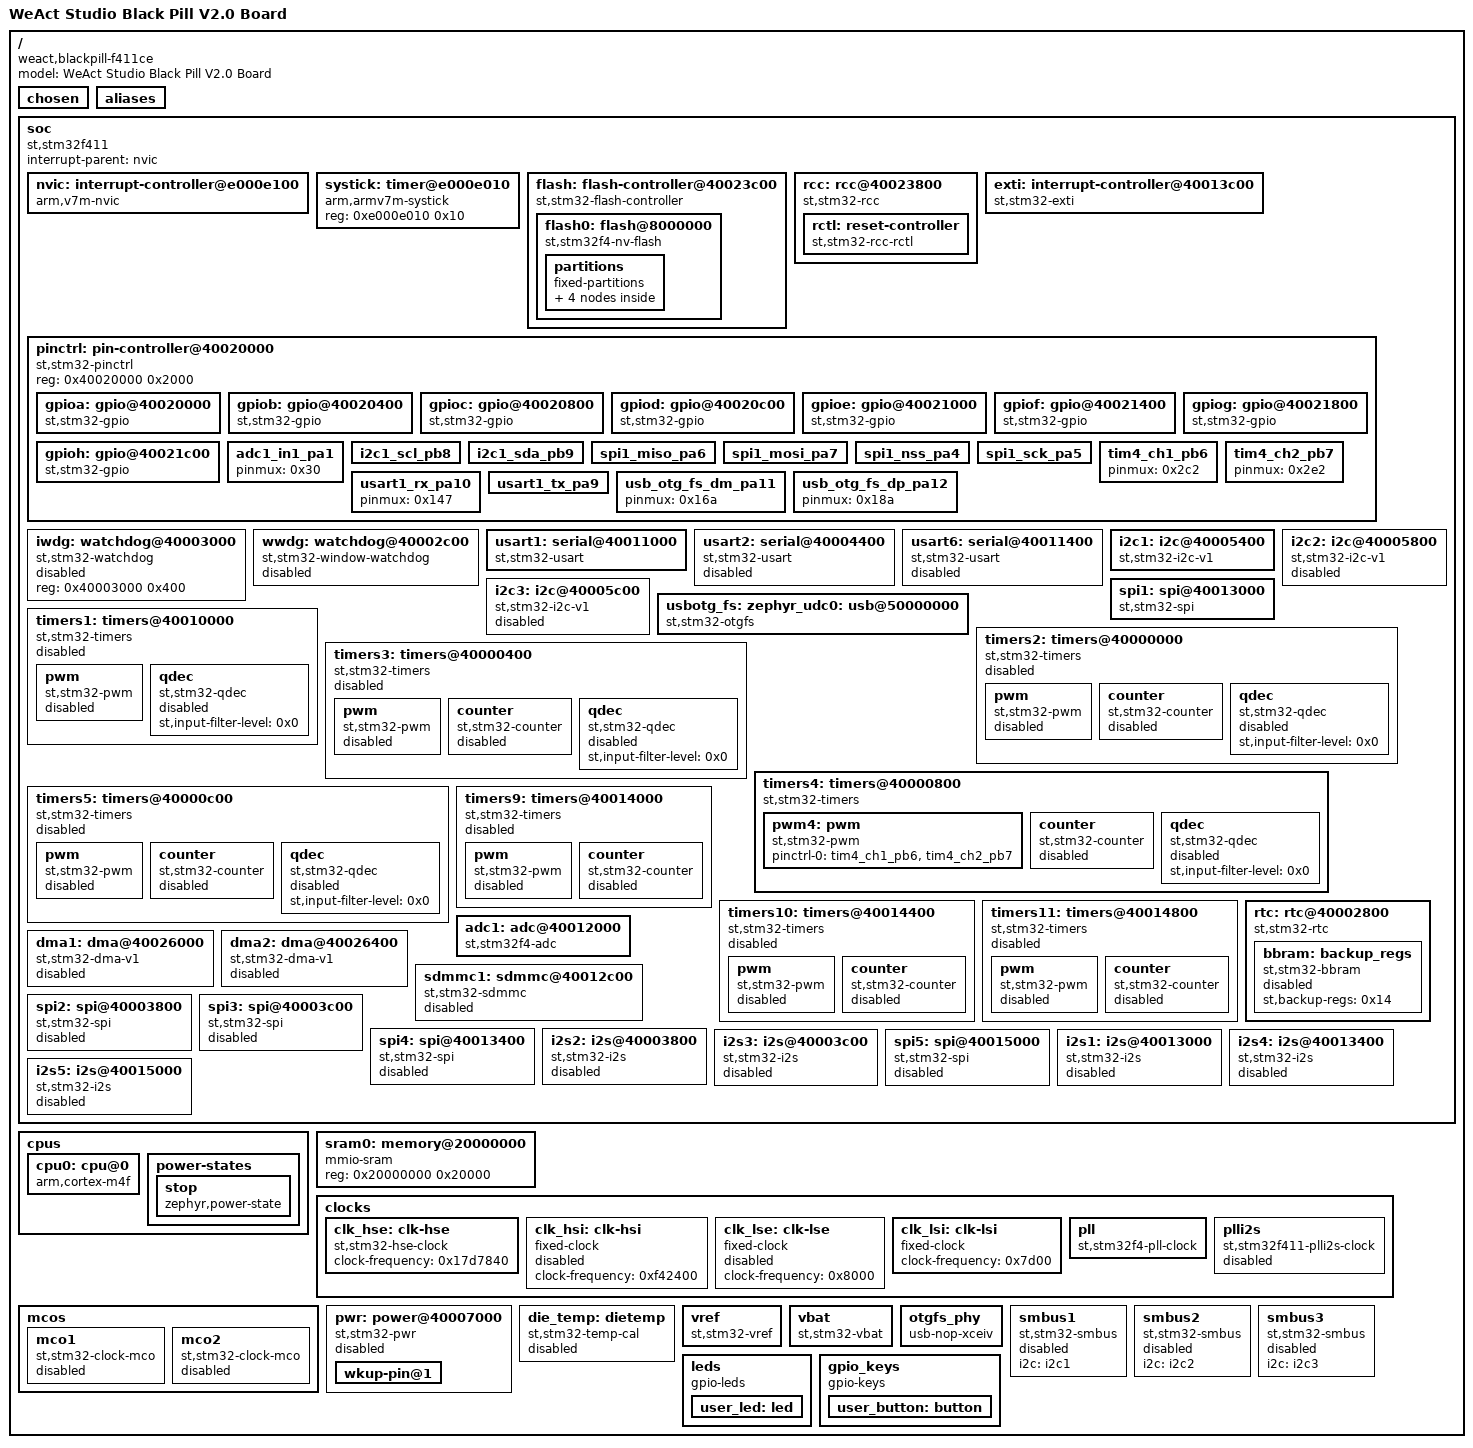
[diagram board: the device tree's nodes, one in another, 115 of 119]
/dts-v1/;

/* node '/' defined in zephyr/dts/common/skeleton.dtsi:9 */
/ {
	#address-cells = < 0x1 >;                     /* in zephyr/dts/common/skeleton.dtsi:10 */
	#size-cells = < 0x1 >;                        /* in zephyr/dts/common/skeleton.dtsi:11 */
	model = "WeAct Studio Black Pill V2.0 Board"; /* in zephyr/boards/weact/blackpill_f411ce/blackpill_f411ce.dts:14 */
	compatible = "weact,blackpill-f411ce";        /* in zephyr/boards/weact/blackpill_f411ce/blackpill_f411ce.dts:15 */

	/* node '/chosen' defined in zephyr/dts/common/skeleton.dtsi:12 */
	chosen {
		zephyr,flash-controller = &flash;        /* in zephyr/dts/arm/st/f4/stm32f4.dtsi:26 */
		zephyr,cortex-m-idle-timer = &rtc;       /* in zephyr/dts/arm/st/f4/stm32f4.dtsi:27 */
		zephyr,console = &usart1;                /* in zephyr/boards/weact/blackpill_f411ce/blackpill_f411ce.dts:18 */
		zephyr,shell-uart = &usart1;             /* in zephyr/boards/weact/blackpill_f411ce/blackpill_f411ce.dts:19 */
		zephyr,sram = &sram0;                    /* in zephyr/boards/weact/blackpill_f411ce/blackpill_f411ce.dts:20 */
		zephyr,flash = &flash0;                  /* in zephyr/boards/weact/blackpill_f411ce/blackpill_f411ce.dts:21 */
		zephyr,code-partition = &boot_partition; /* in bootloader/mcuboot/boot/zephyr/app.overlay:3 */
	};

	/* node '/aliases' defined in zephyr/dts/common/skeleton.dtsi:13 */
	aliases {
		led0 = &user_led;     /* in zephyr/boards/weact/blackpill_f411ce/blackpill_f411ce.dts:42 */
		sw0 = &user_button;   /* in zephyr/boards/weact/blackpill_f411ce/blackpill_f411ce.dts:43 */
		volt-sensor0 = &vref; /* in zephyr/boards/weact/blackpill_f411ce/blackpill_f411ce.dts:44 */
		volt-sensor1 = &vbat; /* in zephyr/boards/weact/blackpill_f411ce/blackpill_f411ce.dts:45 */
	};

	/* node '/soc' defined in zephyr/dts/arm/armv7-m.dtsi:6 */
	soc {
		#address-cells = < 0x1 >;     /* in zephyr/dts/arm/armv7-m.dtsi:7 */
		#size-cells = < 0x1 >;        /* in zephyr/dts/arm/armv7-m.dtsi:8 */
		interrupt-parent = < &nvic >; /* in zephyr/dts/arm/armv7-m.dtsi:10 */
		ranges;                       /* in zephyr/dts/arm/armv7-m.dtsi:11 */
		compatible = "st,stm32f411",
		             "st,stm32f4",
		             "simple-bus";    /* in zephyr/dts/arm/st/f4/stm32f411.dtsi:19 */

		/* node '/soc/interrupt-controller@e000e100' defined in zephyr/dts/arm/armv7-m.dtsi:13 */
		nvic: interrupt-controller@e000e100 {
			#address-cells = < 0x1 >;            /* in zephyr/dts/arm/armv7-m.dtsi:14 */
			compatible = "arm,v7m-nvic";         /* in zephyr/dts/arm/armv7-m.dtsi:15 */
			reg = < 0xe000e100 0xc00 >;          /* in zephyr/dts/arm/armv7-m.dtsi:16 */
			interrupt-controller;                /* in zephyr/dts/arm/armv7-m.dtsi:17 */
			#interrupt-cells = < 0x2 >;          /* in zephyr/dts/arm/armv7-m.dtsi:18 */
			arm,num-irq-priority-bits = < 0x4 >; /* in zephyr/dts/arm/st/f4/stm32f4.dtsi:663 */
			phandle = < 0x1 >;                   /* in zephyr/dts/arm/armv7-m.dtsi:10 */
		};

		/* node '/soc/timer@e000e010' defined in zephyr/dts/arm/armv7-m.dtsi:21 */
		systick: timer@e000e010 {
			compatible = "arm,armv7m-systick"; /* in zephyr/dts/arm/armv7-m.dtsi:22 */
			reg = < 0xe000e010 0x10 >;         /* in zephyr/dts/arm/armv7-m.dtsi:23 */
		};

		/* node '/soc/flash-controller@40023c00' defined in zephyr/dts/arm/st/f4/stm32f4.dtsi:109 */
		flash: flash-controller@40023c00 {
			compatible = "st,stm32-flash-controller",
			             "st,stm32f4-flash-controller"; /* in zephyr/dts/arm/st/f4/stm32f4.dtsi:110 */
			reg = < 0x40023c00 0x400 >;                 /* in zephyr/dts/arm/st/f4/stm32f4.dtsi:111 */
			interrupts = < 0x4 0x0 >;                   /* in zephyr/dts/arm/st/f4/stm32f4.dtsi:112 */
			#address-cells = < 0x1 >;                   /* in zephyr/dts/arm/st/f4/stm32f4.dtsi:114 */
			#size-cells = < 0x1 >;                      /* in zephyr/dts/arm/st/f4/stm32f4.dtsi:115 */

			/* node '/soc/flash-controller@40023c00/flash@8000000' defined in zephyr/dts/arm/st/f4/stm32f4.dtsi:117 */
			flash0: flash@8000000 {
				compatible = "st,stm32f4-nv-flash",
				             "st,stm32-nv-flash",
				             "soc-nv-flash";        /* in zephyr/dts/arm/st/f4/stm32f4.dtsi:118 */
				write-block-size = < 0x1 >;         /* in zephyr/dts/arm/st/f4/stm32f4.dtsi:121 */
				max-erase-time = < 0xfa0 >;         /* in zephyr/dts/arm/st/f4/stm32f4.dtsi:123 */
				reg = < 0x8000000 0x80000 >;        /* in zephyr/dts/arm/st/f4/stm32f411Xe.dtsi:18 */

				/* node '/soc/flash-controller@40023c00/flash@8000000/partitions' defined in zephyr/boards/weact/blackpill_f411ce/blackpill_f411ce.dts:51 */
				partitions {
					compatible = "fixed-partitions"; /* in zephyr/boards/weact/blackpill_f411ce/blackpill_f411ce.dts:52 */
					#address-cells = < 0x1 >;        /* in zephyr/boards/weact/blackpill_f411ce/blackpill_f411ce.dts:53 */
					#size-cells = < 0x1 >;           /* in zephyr/boards/weact/blackpill_f411ce/blackpill_f411ce.dts:54 */

					/* node '/soc/flash-controller@40023c00/flash@8000000/partitions/partition@0' defined in zephyr/boards/weact/blackpill_f411ce/blackpill_f411ce.dts:56 */
					boot_partition: partition@0 {
						label = "mcuboot";    /* in zephyr/boards/weact/blackpill_f411ce/blackpill_f411ce.dts:57 */
						reg = < 0x0 0x8000 >; /* in zephyr/boards/weact/blackpill_f411ce/blackpill_f411ce.dts:58 */
						read-only;            /* in zephyr/boards/weact/blackpill_f411ce/blackpill_f411ce.dts:59 */
					};

					/* node '/soc/flash-controller@40023c00/flash@8000000/partitions/partition@20000' defined in zephyr/boards/weact/blackpill_f411ce/blackpill_f411ce.dts:68 */
					slot0_partition: partition@20000 {
						label = "image-0";         /* in zephyr/boards/weact/blackpill_f411ce/blackpill_f411ce.dts:69 */
						reg = < 0x20000 0x20000 >; /* in zephyr/boards/weact/blackpill_f411ce/blackpill_f411ce.dts:70 */
					};

					/* node '/soc/flash-controller@40023c00/flash@8000000/partitions/partition@40000' defined in zephyr/boards/weact/blackpill_f411ce/blackpill_f411ce.dts:72 */
					slot1_partition: partition@40000 {
						label = "image-1";         /* in zephyr/boards/weact/blackpill_f411ce/blackpill_f411ce.dts:73 */
						reg = < 0x40000 0x20000 >; /* in zephyr/boards/weact/blackpill_f411ce/blackpill_f411ce.dts:74 */
					};

					/* node '/soc/flash-controller@40023c00/flash@8000000/partitions/partition@60000' defined in zephyr/boards/weact/blackpill_f411ce/blackpill_f411ce.dts:76 */
					scratch_partition: partition@60000 {
						label = "image-scratch";   /* in zephyr/boards/weact/blackpill_f411ce/blackpill_f411ce.dts:77 */
						reg = < 0x60000 0x20000 >; /* in zephyr/boards/weact/blackpill_f411ce/blackpill_f411ce.dts:78 */
					};
				};
			};
		};

		/* node '/soc/rcc@40023800' defined in zephyr/dts/arm/st/f4/stm32f4.dtsi:127 */
		rcc: rcc@40023800 {
			compatible = "st,stm32-rcc";     /* in zephyr/dts/arm/st/f4/stm32f4.dtsi:128 */
			#clock-cells = < 0x2 >;          /* in zephyr/dts/arm/st/f4/stm32f4.dtsi:129 */
			reg = < 0x40023800 0x400 >;      /* in zephyr/dts/arm/st/f4/stm32f4.dtsi:130 */
			clocks = < &pll >;               /* in zephyr/boards/weact/blackpill_f411ce/blackpill_f411ce.dts:153 */
			clock-frequency = < 0x5b8d800 >; /* in zephyr/boards/weact/blackpill_f411ce/blackpill_f411ce.dts:154 */
			ahb-prescaler = < 0x1 >;         /* in zephyr/boards/weact/blackpill_f411ce/blackpill_f411ce.dts:155 */
			apb1-prescaler = < 0x2 >;        /* in zephyr/boards/weact/blackpill_f411ce/blackpill_f411ce.dts:156 */
			apb2-prescaler = < 0x1 >;        /* in zephyr/boards/weact/blackpill_f411ce/blackpill_f411ce.dts:157 */
			phandle = < 0x3 >;               /* in zephyr/dts/arm/st/f4/stm32f4.dtsi:164 */

			/* node '/soc/rcc@40023800/reset-controller' defined in zephyr/dts/arm/st/f4/stm32f4.dtsi:132 */
			rctl: reset-controller {
				compatible = "st,stm32-rcc-rctl"; /* in zephyr/dts/arm/st/f4/stm32f4.dtsi:133 */
				#reset-cells = < 0x1 >;           /* in zephyr/dts/arm/st/f4/stm32f4.dtsi:134 */
				phandle = < 0x4 >;                /* in zephyr/dts/arm/st/f4/stm32f4.dtsi:242 */
			};
		};

		/* node '/soc/interrupt-controller@40013c00' defined in zephyr/dts/arm/st/f4/stm32f4.dtsi:138 */
		exti: interrupt-controller@40013c00 {
			compatible = "st,stm32-exti";  /* in zephyr/dts/arm/st/f4/stm32f4.dtsi:139 */
			interrupt-controller;          /* in zephyr/dts/arm/st/f4/stm32f4.dtsi:140 */
			#interrupt-cells = < 0x1 >;    /* in zephyr/dts/arm/st/f4/stm32f4.dtsi:141 */
			#address-cells = < 0x1 >;      /* in zephyr/dts/arm/st/f4/stm32f4.dtsi:142 */
			reg = < 0x40013c00 0x400 >;    /* in zephyr/dts/arm/st/f4/stm32f4.dtsi:143 */
			num-lines = < 0x10 >;          /* in zephyr/dts/arm/st/f4/stm32f4.dtsi:144 */
			interrupts = < 0x6 0x0 >,
			             < 0x7 0x0 >,
			             < 0x8 0x0 >,
			             < 0x9 0x0 >,
			             < 0xa 0x0 >,
			             < 0x17 0x0 >,
			             < 0x28 0x0 >;     /* in zephyr/dts/arm/st/f4/stm32f4.dtsi:145 */
			interrupt-names = "line0",
			                  "line1",
			                  "line2",
			                  "line3",
			                  "line4",
			                  "line5-9",
			                  "line10-15"; /* in zephyr/dts/arm/st/f4/stm32f4.dtsi:147 */
			line-ranges = < 0x0 0x1 >,
			              < 0x1 0x1 >,
			              < 0x2 0x1 >,
			              < 0x3 0x1 >,
			              < 0x4 0x1 >,
			              < 0x5 0x5 >,
			              < 0xa 0x6 >;     /* in zephyr/dts/arm/st/f4/stm32f4.dtsi:149 */
		};

		/* node '/soc/pin-controller@40020000' defined in zephyr/dts/arm/st/f4/stm32f4.dtsi:153 */
		pinctrl: pin-controller@40020000 {
			compatible = "st,stm32-pinctrl"; /* in zephyr/dts/arm/st/f4/stm32f4.dtsi:154 */
			#address-cells = < 0x1 >;        /* in zephyr/dts/arm/st/f4/stm32f4.dtsi:155 */
			#size-cells = < 0x1 >;           /* in zephyr/dts/arm/st/f4/stm32f4.dtsi:156 */
			reg = < 0x40020000 0x2000 >;     /* in zephyr/dts/arm/st/f4/stm32f4.dtsi:157 */

			/* node '/soc/pin-controller@40020000/gpio@40020000' defined in zephyr/dts/arm/st/f4/stm32f4.dtsi:159 */
			gpioa: gpio@40020000 {
				compatible = "st,stm32-gpio"; /* in zephyr/dts/arm/st/f4/stm32f4.dtsi:160 */
				gpio-controller;              /* in zephyr/dts/arm/st/f4/stm32f4.dtsi:161 */
				#gpio-cells = < 0x2 >;        /* in zephyr/dts/arm/st/f4/stm32f4.dtsi:162 */
				reg = < 0x40020000 0x400 >;   /* in zephyr/dts/arm/st/f4/stm32f4.dtsi:163 */
				clocks = < &rcc 0x30 0x1 >;   /* in zephyr/dts/arm/st/f4/stm32f4.dtsi:164 */
				phandle = < 0x17 >;           /* in zephyr/dts/arm/st/f4/stm32f4.dtsi:602 */
			};

			/* node '/soc/pin-controller@40020000/gpio@40020400' defined in zephyr/dts/arm/st/f4/stm32f4.dtsi:167 */
			gpiob: gpio@40020400 {
				compatible = "st,stm32-gpio"; /* in zephyr/dts/arm/st/f4/stm32f4.dtsi:168 */
				gpio-controller;              /* in zephyr/dts/arm/st/f4/stm32f4.dtsi:169 */
				#gpio-cells = < 0x2 >;        /* in zephyr/dts/arm/st/f4/stm32f4.dtsi:170 */
				reg = < 0x40020400 0x400 >;   /* in zephyr/dts/arm/st/f4/stm32f4.dtsi:171 */
				clocks = < &rcc 0x30 0x2 >;   /* in zephyr/dts/arm/st/f4/stm32f4.dtsi:172 */
			};

			/* node '/soc/pin-controller@40020000/gpio@40020800' defined in zephyr/dts/arm/st/f4/stm32f4.dtsi:175 */
			gpioc: gpio@40020800 {
				compatible = "st,stm32-gpio"; /* in zephyr/dts/arm/st/f4/stm32f4.dtsi:176 */
				gpio-controller;              /* in zephyr/dts/arm/st/f4/stm32f4.dtsi:177 */
				#gpio-cells = < 0x2 >;        /* in zephyr/dts/arm/st/f4/stm32f4.dtsi:178 */
				reg = < 0x40020800 0x400 >;   /* in zephyr/dts/arm/st/f4/stm32f4.dtsi:179 */
				clocks = < &rcc 0x30 0x4 >;   /* in zephyr/dts/arm/st/f4/stm32f4.dtsi:180 */
				phandle = < 0x1c >;           /* in zephyr/boards/weact/blackpill_f411ce/blackpill_f411ce.dts:27 */
			};

			/* node '/soc/pin-controller@40020000/gpio@40020c00' defined in zephyr/dts/arm/st/f4/stm32f4.dtsi:183 */
			gpiod: gpio@40020c00 {
				compatible = "st,stm32-gpio"; /* in zephyr/dts/arm/st/f4/stm32f4.dtsi:184 */
				gpio-controller;              /* in zephyr/dts/arm/st/f4/stm32f4.dtsi:185 */
				#gpio-cells = < 0x2 >;        /* in zephyr/dts/arm/st/f4/stm32f4.dtsi:186 */
				reg = < 0x40020c00 0x400 >;   /* in zephyr/dts/arm/st/f4/stm32f4.dtsi:187 */
				clocks = < &rcc 0x30 0x8 >;   /* in zephyr/dts/arm/st/f4/stm32f4.dtsi:188 */
			};

			/* node '/soc/pin-controller@40020000/gpio@40021000' defined in zephyr/dts/arm/st/f4/stm32f4.dtsi:191 */
			gpioe: gpio@40021000 {
				compatible = "st,stm32-gpio"; /* in zephyr/dts/arm/st/f4/stm32f4.dtsi:192 */
				gpio-controller;              /* in zephyr/dts/arm/st/f4/stm32f4.dtsi:193 */
				#gpio-cells = < 0x2 >;        /* in zephyr/dts/arm/st/f4/stm32f4.dtsi:194 */
				reg = < 0x40021000 0x400 >;   /* in zephyr/dts/arm/st/f4/stm32f4.dtsi:195 */
				clocks = < &rcc 0x30 0x10 >;  /* in zephyr/dts/arm/st/f4/stm32f4.dtsi:196 */
			};

			/* node '/soc/pin-controller@40020000/gpio@40021400' defined in zephyr/dts/arm/st/f4/stm32f4.dtsi:199 */
			gpiof: gpio@40021400 {
				compatible = "st,stm32-gpio"; /* in zephyr/dts/arm/st/f4/stm32f4.dtsi:200 */
				gpio-controller;              /* in zephyr/dts/arm/st/f4/stm32f4.dtsi:201 */
				#gpio-cells = < 0x2 >;        /* in zephyr/dts/arm/st/f4/stm32f4.dtsi:202 */
				reg = < 0x40021400 0x400 >;   /* in zephyr/dts/arm/st/f4/stm32f4.dtsi:203 */
				clocks = < &rcc 0x30 0x20 >;  /* in zephyr/dts/arm/st/f4/stm32f4.dtsi:204 */
			};

			/* node '/soc/pin-controller@40020000/gpio@40021800' defined in zephyr/dts/arm/st/f4/stm32f4.dtsi:207 */
			gpiog: gpio@40021800 {
				compatible = "st,stm32-gpio"; /* in zephyr/dts/arm/st/f4/stm32f4.dtsi:208 */
				gpio-controller;              /* in zephyr/dts/arm/st/f4/stm32f4.dtsi:209 */
				#gpio-cells = < 0x2 >;        /* in zephyr/dts/arm/st/f4/stm32f4.dtsi:210 */
				reg = < 0x40021800 0x400 >;   /* in zephyr/dts/arm/st/f4/stm32f4.dtsi:211 */
				clocks = < &rcc 0x30 0x40 >;  /* in zephyr/dts/arm/st/f4/stm32f4.dtsi:212 */
			};

			/* node '/soc/pin-controller@40020000/gpio@40021c00' defined in zephyr/dts/arm/st/f4/stm32f4.dtsi:215 */
			gpioh: gpio@40021c00 {
				compatible = "st,stm32-gpio"; /* in zephyr/dts/arm/st/f4/stm32f4.dtsi:216 */
				gpio-controller;              /* in zephyr/dts/arm/st/f4/stm32f4.dtsi:217 */
				#gpio-cells = < 0x2 >;        /* in zephyr/dts/arm/st/f4/stm32f4.dtsi:218 */
				reg = < 0x40021c00 0x400 >;   /* in zephyr/dts/arm/st/f4/stm32f4.dtsi:219 */
				clocks = < &rcc 0x30 0x80 >;  /* in zephyr/dts/arm/st/f4/stm32f4.dtsi:220 */
			};

			/* node '/soc/pin-controller@40020000/adc1_in1_pa1' defined in modules/hal/stm32/dts/st/f4/stm32f411c(c-e)ux-pinctrl.dtsi:19 */
			adc1_in1_pa1: adc1_in1_pa1 {
				pinmux = < 0x30 >;  /* in modules/hal/stm32/dts/st/f4/stm32f411c(c-e)ux-pinctrl.dtsi:20 */
				phandle = < 0x12 >; /* in zephyr/boards/weact/blackpill_f411ce/blackpill_f411ce.dts:127 */
			};

			/* node '/soc/pin-controller@40020000/i2c1_scl_pb8' defined in modules/hal/stm32/dts/st/f4/stm32f411c(c-e)ux-pinctrl.dtsi:209 */
			i2c1_scl_pb8: i2c1_scl_pb8 {
				pinmux = < 0x304 >; /* in modules/hal/stm32/dts/st/f4/stm32f411c(c-e)ux-pinctrl.dtsi:210 */
				bias-pull-up;       /* in modules/hal/stm32/dts/st/f4/stm32f411c(c-e)ux-pinctrl.dtsi:211 */
				drive-open-drain;   /* in modules/hal/stm32/dts/st/f4/stm32f411c(c-e)ux-pinctrl.dtsi:212 */
				phandle = < 0x7 >;  /* in zephyr/boards/weact/blackpill_f411ce/blackpill_f411ce.dts:101 */
			};

			/* node '/soc/pin-controller@40020000/i2c1_sda_pb9' defined in modules/hal/stm32/dts/st/f4/stm32f411c(c-e)ux-pinctrl.dtsi:235 */
			i2c1_sda_pb9: i2c1_sda_pb9 {
				pinmux = < 0x324 >; /* in modules/hal/stm32/dts/st/f4/stm32f411c(c-e)ux-pinctrl.dtsi:236 */
				bias-pull-up;       /* in modules/hal/stm32/dts/st/f4/stm32f411c(c-e)ux-pinctrl.dtsi:237 */
				drive-open-drain;   /* in modules/hal/stm32/dts/st/f4/stm32f411c(c-e)ux-pinctrl.dtsi:238 */
				phandle = < 0x8 >;  /* in zephyr/boards/weact/blackpill_f411ce/blackpill_f411ce.dts:101 */
			};

			/* node '/soc/pin-controller@40020000/spi1_miso_pa6' defined in modules/hal/stm32/dts/st/f4/stm32f411c(c-e)ux-pinctrl.dtsi:504 */
			spi1_miso_pa6: spi1_miso_pa6 {
				pinmux = < 0xc5 >; /* in modules/hal/stm32/dts/st/f4/stm32f411c(c-e)ux-pinctrl.dtsi:505 */
				bias-pull-down;    /* in modules/hal/stm32/dts/st/f4/stm32f411c(c-e)ux-pinctrl.dtsi:506 */
				phandle = < 0xb >; /* in zephyr/boards/weact/blackpill_f411ce/blackpill_f411ce.dts:108 */
			};

			/* node '/soc/pin-controller@40020000/spi1_mosi_pa7' defined in modules/hal/stm32/dts/st/f4/stm32f411c(c-e)ux-pinctrl.dtsi:536 */
			spi1_mosi_pa7: spi1_mosi_pa7 {
				pinmux = < 0xe5 >; /* in modules/hal/stm32/dts/st/f4/stm32f411c(c-e)ux-pinctrl.dtsi:537 */
				bias-pull-down;    /* in modules/hal/stm32/dts/st/f4/stm32f411c(c-e)ux-pinctrl.dtsi:538 */
				phandle = < 0xc >; /* in zephyr/boards/weact/blackpill_f411ce/blackpill_f411ce.dts:108 */
			};

			/* node '/soc/pin-controller@40020000/spi1_nss_pa4' defined in modules/hal/stm32/dts/st/f4/stm32f411c(c-e)ux-pinctrl.dtsi:573 */
			spi1_nss_pa4: spi1_nss_pa4 {
				pinmux = < 0x85 >; /* in modules/hal/stm32/dts/st/f4/stm32f411c(c-e)ux-pinctrl.dtsi:574 */
				bias-pull-up;      /* in modules/hal/stm32/dts/st/f4/stm32f411c(c-e)ux-pinctrl.dtsi:575 */
				phandle = < 0xa >; /* in zephyr/boards/weact/blackpill_f411ce/blackpill_f411ce.dts:108 */
			};

			/* node '/soc/pin-controller@40020000/spi1_sck_pa5' defined in modules/hal/stm32/dts/st/f4/stm32f411c(c-e)ux-pinctrl.dtsi:615 */
			spi1_sck_pa5: spi1_sck_pa5 {
				pinmux = < 0xa5 >;             /* in modules/hal/stm32/dts/st/f4/stm32f411c(c-e)ux-pinctrl.dtsi:616 */
				bias-pull-down;                /* in modules/hal/stm32/dts/st/f4/stm32f411c(c-e)ux-pinctrl.dtsi:617 */
				slew-rate = "very-high-speed"; /* in modules/hal/stm32/dts/st/f4/stm32f411c(c-e)ux-pinctrl.dtsi:618 */
				phandle = < 0x9 >;             /* in zephyr/boards/weact/blackpill_f411ce/blackpill_f411ce.dts:108 */
			};

			/* node '/soc/pin-controller@40020000/tim4_ch1_pb6' defined in modules/hal/stm32/dts/st/f4/stm32f411c(c-e)ux-pinctrl.dtsi:779 */
			tim4_ch1_pb6: tim4_ch1_pb6 {
				pinmux = < 0x2c2 >; /* in modules/hal/stm32/dts/st/f4/stm32f411c(c-e)ux-pinctrl.dtsi:780 */
				phandle = < 0x10 >; /* in zephyr/boards/weact/blackpill_f411ce/blackpill_f411ce.dts:88 */
			};

			/* node '/soc/pin-controller@40020000/tim4_ch2_pb7' defined in modules/hal/stm32/dts/st/f4/stm32f411c(c-e)ux-pinctrl.dtsi:783 */
			tim4_ch2_pb7: tim4_ch2_pb7 {
				pinmux = < 0x2e2 >; /* in modules/hal/stm32/dts/st/f4/stm32f411c(c-e)ux-pinctrl.dtsi:784 */
				phandle = < 0x11 >; /* in zephyr/boards/weact/blackpill_f411ce/blackpill_f411ce.dts:88 */
			};

			/* node '/soc/pin-controller@40020000/usart1_rx_pa10' defined in modules/hal/stm32/dts/st/f4/stm32f411c(c-e)ux-pinctrl.dtsi:845 */
			usart1_rx_pa10: usart1_rx_pa10 {
				pinmux = < 0x147 >; /* in modules/hal/stm32/dts/st/f4/stm32f411c(c-e)ux-pinctrl.dtsi:846 */
				phandle = < 0x6 >;  /* in zephyr/boards/weact/blackpill_f411ce/blackpill_f411ce.dts:94 */
			};

			/* node '/soc/pin-controller@40020000/usart1_tx_pa9' defined in modules/hal/stm32/dts/st/f4/stm32f411c(c-e)ux-pinctrl.dtsi:867 */
			usart1_tx_pa9: usart1_tx_pa9 {
				pinmux = < 0x127 >; /* in modules/hal/stm32/dts/st/f4/stm32f411c(c-e)ux-pinctrl.dtsi:868 */
				bias-pull-up;       /* in modules/hal/stm32/dts/st/f4/stm32f411c(c-e)ux-pinctrl.dtsi:869 */
				phandle = < 0x5 >;  /* in zephyr/boards/weact/blackpill_f411ce/blackpill_f411ce.dts:94 */
			};

			/* node '/soc/pin-controller@40020000/usb_otg_fs_dm_pa11' defined in modules/hal/stm32/dts/st/f4/stm32f411c(c-e)ux-pinctrl.dtsi:906 */
			usb_otg_fs_dm_pa11: usb_otg_fs_dm_pa11 {
				pinmux = < 0x16a >; /* in modules/hal/stm32/dts/st/f4/stm32f411c(c-e)ux-pinctrl.dtsi:907 */
				phandle = < 0xe >;  /* in zephyr/boards/weact/blackpill_f411ce/blackpill_f411ce.dts:121 */
			};

			/* node '/soc/pin-controller@40020000/usb_otg_fs_dp_pa12' defined in modules/hal/stm32/dts/st/f4/stm32f411c(c-e)ux-pinctrl.dtsi:910 */
			usb_otg_fs_dp_pa12: usb_otg_fs_dp_pa12 {
				pinmux = < 0x18a >; /* in modules/hal/stm32/dts/st/f4/stm32f411c(c-e)ux-pinctrl.dtsi:911 */
				phandle = < 0xf >;  /* in zephyr/boards/weact/blackpill_f411ce/blackpill_f411ce.dts:121 */
			};
		};

		/* node '/soc/watchdog@40003000' defined in zephyr/dts/arm/st/f4/stm32f4.dtsi:224 */
		iwdg: watchdog@40003000 {
			compatible = "st,stm32-watchdog"; /* in zephyr/dts/arm/st/f4/stm32f4.dtsi:225 */
			reg = < 0x40003000 0x400 >;       /* in zephyr/dts/arm/st/f4/stm32f4.dtsi:226 */
			status = "disabled";              /* in zephyr/dts/arm/st/f4/stm32f4.dtsi:227 */
		};

		/* node '/soc/watchdog@40002c00' defined in zephyr/dts/arm/st/f4/stm32f4.dtsi:230 */
		wwdg: watchdog@40002c00 {
			compatible = "st,stm32-window-watchdog"; /* in zephyr/dts/arm/st/f4/stm32f4.dtsi:231 */
			reg = < 0x40002c00 0x400 >;              /* in zephyr/dts/arm/st/f4/stm32f4.dtsi:232 */
			clocks = < &rcc 0x40 0x800 >;            /* in zephyr/dts/arm/st/f4/stm32f4.dtsi:233 */
			interrupts = < 0x0 0x7 >;                /* in zephyr/dts/arm/st/f4/stm32f4.dtsi:234 */
			status = "disabled";                     /* in zephyr/dts/arm/st/f4/stm32f4.dtsi:235 */
		};

		/* node '/soc/serial@40011000' defined in zephyr/dts/arm/st/f4/stm32f4.dtsi:238 */
		usart1: serial@40011000 {
			compatible = "st,stm32-usart",
			             "st,stm32-uart";                   /* in zephyr/dts/arm/st/f4/stm32f4.dtsi:239 */
			reg = < 0x40011000 0x400 >;                     /* in zephyr/dts/arm/st/f4/stm32f4.dtsi:240 */
			clocks = < &rcc 0x44 0x10 >;                    /* in zephyr/dts/arm/st/f4/stm32f4.dtsi:241 */
			resets = < &rctl 0x484 >;                       /* in zephyr/dts/arm/st/f4/stm32f4.dtsi:242 */
			interrupts = < 0x25 0x0 >;                      /* in zephyr/dts/arm/st/f4/stm32f4.dtsi:243 */
			pinctrl-0 = < &usart1_tx_pa9 &usart1_rx_pa10 >; /* in zephyr/boards/weact/blackpill_f411ce/blackpill_f411ce.dts:94 */
			pinctrl-names = "default";                      /* in zephyr/boards/weact/blackpill_f411ce/blackpill_f411ce.dts:95 */
			status = "okay";                                /* in zephyr/boards/weact/blackpill_f411ce/blackpill_f411ce.dts:96 */
			current-speed = < 0x1c200 >;                    /* in zephyr/boards/weact/blackpill_f411ce/blackpill_f411ce.dts:97 */
		};

		/* node '/soc/serial@40004400' defined in zephyr/dts/arm/st/f4/stm32f4.dtsi:247 */
		usart2: serial@40004400 {
			compatible = "st,stm32-usart",
			             "st,stm32-uart";   /* in zephyr/dts/arm/st/f4/stm32f4.dtsi:248 */
			reg = < 0x40004400 0x400 >;     /* in zephyr/dts/arm/st/f4/stm32f4.dtsi:249 */
			clocks = < &rcc 0x40 0x20000 >; /* in zephyr/dts/arm/st/f4/stm32f4.dtsi:250 */
			resets = < &rctl 0x411 >;       /* in zephyr/dts/arm/st/f4/stm32f4.dtsi:251 */
			interrupts = < 0x26 0x0 >;      /* in zephyr/dts/arm/st/f4/stm32f4.dtsi:252 */
			status = "disabled";            /* in zephyr/dts/arm/st/f4/stm32f4.dtsi:253 */
		};

		/* node '/soc/serial@40011400' defined in zephyr/dts/arm/st/f4/stm32f4.dtsi:256 */
		usart6: serial@40011400 {
			compatible = "st,stm32-usart",
			             "st,stm32-uart";  /* in zephyr/dts/arm/st/f4/stm32f4.dtsi:257 */
			reg = < 0x40011400 0x400 >;    /* in zephyr/dts/arm/st/f4/stm32f4.dtsi:258 */
			clocks = < &rcc 0x44 0x20 >;   /* in zephyr/dts/arm/st/f4/stm32f4.dtsi:259 */
			resets = < &rctl 0x485 >;      /* in zephyr/dts/arm/st/f4/stm32f4.dtsi:260 */
			interrupts = < 0x47 0x0 >;     /* in zephyr/dts/arm/st/f4/stm32f4.dtsi:261 */
			status = "disabled";           /* in zephyr/dts/arm/st/f4/stm32f4.dtsi:262 */
		};

		/* node '/soc/i2c@40005400' defined in zephyr/dts/arm/st/f4/stm32f4.dtsi:265 */
		i2c1: i2c@40005400 {
			compatible = "st,stm32-i2c-v1";              /* in zephyr/dts/arm/st/f4/stm32f4.dtsi:266 */
			#address-cells = < 0x1 >;                    /* in zephyr/dts/arm/st/f4/stm32f4.dtsi:268 */
			#size-cells = < 0x0 >;                       /* in zephyr/dts/arm/st/f4/stm32f4.dtsi:269 */
			reg = < 0x40005400 0x400 >;                  /* in zephyr/dts/arm/st/f4/stm32f4.dtsi:270 */
			clocks = < &rcc 0x40 0x200000 >;             /* in zephyr/dts/arm/st/f4/stm32f4.dtsi:271 */
			interrupts = < 0x1f 0x0 >,
			             < 0x20 0x0 >;                   /* in zephyr/dts/arm/st/f4/stm32f4.dtsi:272 */
			interrupt-names = "event",
			                  "error";                   /* in zephyr/dts/arm/st/f4/stm32f4.dtsi:273 */
			pinctrl-0 = < &i2c1_scl_pb8 &i2c1_sda_pb9 >; /* in zephyr/boards/weact/blackpill_f411ce/blackpill_f411ce.dts:101 */
			pinctrl-names = "default";                   /* in zephyr/boards/weact/blackpill_f411ce/blackpill_f411ce.dts:102 */
			status = "okay";                             /* in zephyr/boards/weact/blackpill_f411ce/blackpill_f411ce.dts:103 */
			clock-frequency = < 0x61a80 >;               /* in zephyr/boards/weact/blackpill_f411ce/blackpill_f411ce.dts:104 */
			phandle = < 0x19 >;                          /* in zephyr/dts/arm/st/f4/stm32f4.dtsi:641 */
		};

		/* node '/soc/i2c@40005800' defined in zephyr/dts/arm/st/f4/stm32f4.dtsi:277 */
		i2c2: i2c@40005800 {
			compatible = "st,stm32-i2c-v1";  /* in zephyr/dts/arm/st/f4/stm32f4.dtsi:278 */
			clock-frequency = < 0x186a0 >;   /* in zephyr/dts/arm/st/f4/stm32f4.dtsi:279 */
			#address-cells = < 0x1 >;        /* in zephyr/dts/arm/st/f4/stm32f4.dtsi:280 */
			#size-cells = < 0x0 >;           /* in zephyr/dts/arm/st/f4/stm32f4.dtsi:281 */
			reg = < 0x40005800 0x400 >;      /* in zephyr/dts/arm/st/f4/stm32f4.dtsi:282 */
			clocks = < &rcc 0x40 0x400000 >; /* in zephyr/dts/arm/st/f4/stm32f4.dtsi:283 */
			interrupts = < 0x21 0x0 >,
			             < 0x22 0x0 >;       /* in zephyr/dts/arm/st/f4/stm32f4.dtsi:284 */
			interrupt-names = "event",
			                  "error";       /* in zephyr/dts/arm/st/f4/stm32f4.dtsi:285 */
			status = "disabled";             /* in zephyr/dts/arm/st/f4/stm32f4.dtsi:286 */
			phandle = < 0x1a >;              /* in zephyr/dts/arm/st/f4/stm32f4.dtsi:649 */
		};

		/* node '/soc/i2c@40005c00' defined in zephyr/dts/arm/st/f4/stm32f4.dtsi:289 */
		i2c3: i2c@40005c00 {
			compatible = "st,stm32-i2c-v1";  /* in zephyr/dts/arm/st/f4/stm32f4.dtsi:290 */
			clock-frequency = < 0x186a0 >;   /* in zephyr/dts/arm/st/f4/stm32f4.dtsi:291 */
			#address-cells = < 0x1 >;        /* in zephyr/dts/arm/st/f4/stm32f4.dtsi:292 */
			#size-cells = < 0x0 >;           /* in zephyr/dts/arm/st/f4/stm32f4.dtsi:293 */
			reg = < 0x40005c00 0x400 >;      /* in zephyr/dts/arm/st/f4/stm32f4.dtsi:294 */
			clocks = < &rcc 0x40 0x800000 >; /* in zephyr/dts/arm/st/f4/stm32f4.dtsi:295 */
			interrupts = < 0x48 0x0 >,
			             < 0x49 0x0 >;       /* in zephyr/dts/arm/st/f4/stm32f4.dtsi:296 */
			interrupt-names = "event",
			                  "error";       /* in zephyr/dts/arm/st/f4/stm32f4.dtsi:297 */
			status = "disabled";             /* in zephyr/dts/arm/st/f4/stm32f4.dtsi:298 */
			phandle = < 0x1b >;              /* in zephyr/dts/arm/st/f4/stm32f4.dtsi:657 */
		};

		/* node '/soc/spi@40013000' defined in zephyr/dts/arm/st/f4/stm32f4.dtsi:301 */
		spi1: spi@40013000 {
			compatible = "st,stm32-spi";                                               /* in zephyr/dts/arm/st/f4/stm32f4.dtsi:302 */
			#address-cells = < 0x1 >;                                                  /* in zephyr/dts/arm/st/f4/stm32f4.dtsi:303 */
			#size-cells = < 0x0 >;                                                     /* in zephyr/dts/arm/st/f4/stm32f4.dtsi:304 */
			reg = < 0x40013000 0x400 >;                                                /* in zephyr/dts/arm/st/f4/stm32f4.dtsi:305 */
			clocks = < &rcc 0x44 0x1000 >;                                             /* in zephyr/dts/arm/st/f4/stm32f4.dtsi:306 */
			interrupts = < 0x23 0x5 >;                                                 /* in zephyr/dts/arm/st/f4/stm32f4.dtsi:307 */
			pinctrl-0 = < &spi1_sck_pa5 &spi1_nss_pa4 &spi1_miso_pa6 &spi1_mosi_pa7 >; /* in zephyr/boards/weact/blackpill_f411ce/blackpill_f411ce.dts:108 */
			pinctrl-names = "default";                                                 /* in zephyr/boards/weact/blackpill_f411ce/blackpill_f411ce.dts:110 */
			status = "okay";                                                           /* in zephyr/boards/weact/blackpill_f411ce/blackpill_f411ce.dts:111 */
		};

		/* node '/soc/usb@50000000' defined in zephyr/dts/arm/st/f4/stm32f4.dtsi:311 */
		usbotg_fs: zephyr_udc0: usb@50000000 {
			compatible = "st,stm32-otgfs";                           /* in zephyr/dts/arm/st/f4/stm32f4.dtsi:312 */
			reg = < 0x50000000 0x40000 >;                            /* in zephyr/dts/arm/st/f4/stm32f4.dtsi:313 */
			interrupts = < 0x43 0x0 >;                               /* in zephyr/dts/arm/st/f4/stm32f4.dtsi:314 */
			interrupt-names = "otgfs";                               /* in zephyr/dts/arm/st/f4/stm32f4.dtsi:315 */
			num-bidir-endpoints = < 0x4 >;                           /* in zephyr/dts/arm/st/f4/stm32f4.dtsi:316 */
			ram-size = < 0x500 >;                                    /* in zephyr/dts/arm/st/f4/stm32f4.dtsi:317 */
			maximum-speed = "full-speed";                            /* in zephyr/dts/arm/st/f4/stm32f4.dtsi:318 */
			phys = < &otgfs_phy >;                                   /* in zephyr/dts/arm/st/f4/stm32f4.dtsi:319 */
			clocks = < &rcc 0x34 0x80 >,
			         < &rcc 0x7 0xff >;                              /* in zephyr/dts/arm/st/f4/stm32f4.dtsi:320 */
			pinctrl-0 = < &usb_otg_fs_dm_pa11 &usb_otg_fs_dp_pa12 >; /* in zephyr/boards/weact/blackpill_f411ce/blackpill_f411ce.dts:121 */
			pinctrl-names = "default";                               /* in zephyr/boards/weact/blackpill_f411ce/blackpill_f411ce.dts:122 */
			status = "okay";                                         /* in zephyr/boards/weact/blackpill_f411ce/blackpill_f411ce.dts:123 */
		};

		/* node '/soc/timers@40010000' defined in zephyr/dts/arm/st/f4/stm32f4.dtsi:325 */
		timers1: timers@40010000 {
			compatible = "st,stm32-timers"; /* in zephyr/dts/arm/st/f4/stm32f4.dtsi:326 */
			reg = < 0x40010000 0x400 >;     /* in zephyr/dts/arm/st/f4/stm32f4.dtsi:327 */
			clocks = < &rcc 0x44 0x1 >;     /* in zephyr/dts/arm/st/f4/stm32f4.dtsi:328 */
			resets = < &rctl 0x480 >;       /* in zephyr/dts/arm/st/f4/stm32f4.dtsi:329 */
			interrupts = < 0x18 0x0 >,
			             < 0x19 0x0 >,
			             < 0x1a 0x0 >,
			             < 0x1b 0x0 >;      /* in zephyr/dts/arm/st/f4/stm32f4.dtsi:330 */
			interrupt-names = "brk",
			                  "up",
			                  "trgcom",
			                  "cc";         /* in zephyr/dts/arm/st/f4/stm32f4.dtsi:331 */
			st,prescaler = < 0x0 >;         /* in zephyr/dts/arm/st/f4/stm32f4.dtsi:332 */
			status = "disabled";            /* in zephyr/dts/arm/st/f4/stm32f4.dtsi:333 */

			/* node '/soc/timers@40010000/pwm' defined in zephyr/dts/arm/st/f4/stm32f4.dtsi:335 */
			pwm {
				compatible = "st,stm32-pwm"; /* in zephyr/dts/arm/st/f4/stm32f4.dtsi:336 */
				status = "disabled";         /* in zephyr/dts/arm/st/f4/stm32f4.dtsi:337 */
				#pwm-cells = < 0x3 >;        /* in zephyr/dts/arm/st/f4/stm32f4.dtsi:338 */
			};

			/* node '/soc/timers@40010000/qdec' defined in zephyr/dts/arm/st/f4/stm32f4.dtsi:341 */
			qdec {
				compatible = "st,stm32-qdec";    /* in zephyr/dts/arm/st/f4/stm32f4.dtsi:342 */
				status = "disabled";             /* in zephyr/dts/arm/st/f4/stm32f4.dtsi:343 */
				st,input-filter-level = < 0x0 >; /* in zephyr/dts/arm/st/f4/stm32f4.dtsi:344 */
			};
		};

		/* node '/soc/timers@40000000' defined in zephyr/dts/arm/st/f4/stm32f4.dtsi:348 */
		timers2: timers@40000000 {
			compatible = "st,stm32-timers"; /* in zephyr/dts/arm/st/f4/stm32f4.dtsi:349 */
			reg = < 0x40000000 0x400 >;     /* in zephyr/dts/arm/st/f4/stm32f4.dtsi:350 */
			clocks = < &rcc 0x40 0x1 >;     /* in zephyr/dts/arm/st/f4/stm32f4.dtsi:351 */
			resets = < &rctl 0x400 >;       /* in zephyr/dts/arm/st/f4/stm32f4.dtsi:352 */
			interrupts = < 0x1c 0x0 >;      /* in zephyr/dts/arm/st/f4/stm32f4.dtsi:353 */
			interrupt-names = "global";     /* in zephyr/dts/arm/st/f4/stm32f4.dtsi:354 */
			st,prescaler = < 0x0 >;         /* in zephyr/dts/arm/st/f4/stm32f4.dtsi:355 */
			status = "disabled";            /* in zephyr/dts/arm/st/f4/stm32f4.dtsi:356 */

			/* node '/soc/timers@40000000/pwm' defined in zephyr/dts/arm/st/f4/stm32f4.dtsi:358 */
			pwm {
				compatible = "st,stm32-pwm"; /* in zephyr/dts/arm/st/f4/stm32f4.dtsi:359 */
				status = "disabled";         /* in zephyr/dts/arm/st/f4/stm32f4.dtsi:360 */
				#pwm-cells = < 0x3 >;        /* in zephyr/dts/arm/st/f4/stm32f4.dtsi:361 */
			};

			/* node '/soc/timers@40000000/counter' defined in zephyr/dts/arm/st/f4/stm32f4.dtsi:364 */
			counter {
				compatible = "st,stm32-counter"; /* in zephyr/dts/arm/st/f4/stm32f4.dtsi:365 */
				status = "disabled";             /* in zephyr/dts/arm/st/f4/stm32f4.dtsi:366 */
			};

			/* node '/soc/timers@40000000/qdec' defined in zephyr/dts/arm/st/f4/stm32f4.dtsi:369 */
			qdec {
				compatible = "st,stm32-qdec";    /* in zephyr/dts/arm/st/f4/stm32f4.dtsi:370 */
				status = "disabled";             /* in zephyr/dts/arm/st/f4/stm32f4.dtsi:371 */
				st,input-filter-level = < 0x0 >; /* in zephyr/dts/arm/st/f4/stm32f4.dtsi:372 */
			};
		};

		/* node '/soc/timers@40000400' defined in zephyr/dts/arm/st/f4/stm32f4.dtsi:376 */
		timers3: timers@40000400 {
			compatible = "st,stm32-timers"; /* in zephyr/dts/arm/st/f4/stm32f4.dtsi:377 */
			reg = < 0x40000400 0x400 >;     /* in zephyr/dts/arm/st/f4/stm32f4.dtsi:378 */
			clocks = < &rcc 0x40 0x2 >;     /* in zephyr/dts/arm/st/f4/stm32f4.dtsi:379 */
			resets = < &rctl 0x401 >;       /* in zephyr/dts/arm/st/f4/stm32f4.dtsi:380 */
			interrupts = < 0x1d 0x0 >;      /* in zephyr/dts/arm/st/f4/stm32f4.dtsi:381 */
			interrupt-names = "global";     /* in zephyr/dts/arm/st/f4/stm32f4.dtsi:382 */
			st,prescaler = < 0x0 >;         /* in zephyr/dts/arm/st/f4/stm32f4.dtsi:383 */
			status = "disabled";            /* in zephyr/dts/arm/st/f4/stm32f4.dtsi:384 */

			/* node '/soc/timers@40000400/pwm' defined in zephyr/dts/arm/st/f4/stm32f4.dtsi:386 */
			pwm {
				compatible = "st,stm32-pwm"; /* in zephyr/dts/arm/st/f4/stm32f4.dtsi:387 */
				status = "disabled";         /* in zephyr/dts/arm/st/f4/stm32f4.dtsi:388 */
				#pwm-cells = < 0x3 >;        /* in zephyr/dts/arm/st/f4/stm32f4.dtsi:389 */
			};

			/* node '/soc/timers@40000400/counter' defined in zephyr/dts/arm/st/f4/stm32f4.dtsi:392 */
			counter {
				compatible = "st,stm32-counter"; /* in zephyr/dts/arm/st/f4/stm32f4.dtsi:393 */
				status = "disabled";             /* in zephyr/dts/arm/st/f4/stm32f4.dtsi:394 */
			};

			/* node '/soc/timers@40000400/qdec' defined in zephyr/dts/arm/st/f4/stm32f4.dtsi:397 */
			qdec {
				compatible = "st,stm32-qdec";    /* in zephyr/dts/arm/st/f4/stm32f4.dtsi:398 */
				status = "disabled";             /* in zephyr/dts/arm/st/f4/stm32f4.dtsi:399 */
				st,input-filter-level = < 0x0 >; /* in zephyr/dts/arm/st/f4/stm32f4.dtsi:400 */
			};
		};

		/* node '/soc/timers@40000800' defined in zephyr/dts/arm/st/f4/stm32f4.dtsi:404 */
		timers4: timers@40000800 {
			compatible = "st,stm32-timers"; /* in zephyr/dts/arm/st/f4/stm32f4.dtsi:405 */
			reg = < 0x40000800 0x400 >;     /* in zephyr/dts/arm/st/f4/stm32f4.dtsi:406 */
			clocks = < &rcc 0x40 0x4 >;     /* in zephyr/dts/arm/st/f4/stm32f4.dtsi:407 */
			resets = < &rctl 0x402 >;       /* in zephyr/dts/arm/st/f4/stm32f4.dtsi:408 */
			interrupts = < 0x1e 0x0 >;      /* in zephyr/dts/arm/st/f4/stm32f4.dtsi:409 */
			interrupt-names = "global";     /* in zephyr/dts/arm/st/f4/stm32f4.dtsi:410 */
			st,prescaler = < 0x0 >;         /* in zephyr/dts/arm/st/f4/stm32f4.dtsi:411 */
			status = "okay";                /* in zephyr/boards/weact/blackpill_f411ce/blackpill_f411ce.dts:84 */

			/* node '/soc/timers@40000800/pwm' defined in zephyr/dts/arm/st/f4/stm32f4.dtsi:414 */
			pwm4: pwm {
				compatible = "st,stm32-pwm";                 /* in zephyr/dts/arm/st/f4/stm32f4.dtsi:415 */
				#pwm-cells = < 0x3 >;                        /* in zephyr/dts/arm/st/f4/stm32f4.dtsi:417 */
				status = "okay";                             /* in zephyr/boards/weact/blackpill_f411ce/blackpill_f411ce.dts:87 */
				pinctrl-0 = < &tim4_ch1_pb6 &tim4_ch2_pb7 >; /* in zephyr/boards/weact/blackpill_f411ce/blackpill_f411ce.dts:88 */
				pinctrl-names = "default";                   /* in zephyr/boards/weact/blackpill_f411ce/blackpill_f411ce.dts:89 */
			};

			/* node '/soc/timers@40000800/counter' defined in zephyr/dts/arm/st/f4/stm32f4.dtsi:420 */
			counter {
				compatible = "st,stm32-counter"; /* in zephyr/dts/arm/st/f4/stm32f4.dtsi:421 */
				status = "disabled";             /* in zephyr/dts/arm/st/f4/stm32f4.dtsi:422 */
			};

			/* node '/soc/timers@40000800/qdec' defined in zephyr/dts/arm/st/f4/stm32f4.dtsi:425 */
			qdec {
				compatible = "st,stm32-qdec";    /* in zephyr/dts/arm/st/f4/stm32f4.dtsi:426 */
				status = "disabled";             /* in zephyr/dts/arm/st/f4/stm32f4.dtsi:427 */
				st,input-filter-level = < 0x0 >; /* in zephyr/dts/arm/st/f4/stm32f4.dtsi:428 */
			};
		};

		/* node '/soc/timers@40000c00' defined in zephyr/dts/arm/st/f4/stm32f4.dtsi:432 */
		timers5: timers@40000c00 {
			compatible = "st,stm32-timers"; /* in zephyr/dts/arm/st/f4/stm32f4.dtsi:433 */
			reg = < 0x40000c00 0x400 >;     /* in zephyr/dts/arm/st/f4/stm32f4.dtsi:434 */
			clocks = < &rcc 0x40 0x8 >;     /* in zephyr/dts/arm/st/f4/stm32f4.dtsi:435 */
			resets = < &rctl 0x403 >;       /* in zephyr/dts/arm/st/f4/stm32f4.dtsi:436 */
			interrupts = < 0x32 0x0 >;      /* in zephyr/dts/arm/st/f4/stm32f4.dtsi:437 */
			interrupt-names = "global";     /* in zephyr/dts/arm/st/f4/stm32f4.dtsi:438 */
			st,prescaler = < 0x0 >;         /* in zephyr/dts/arm/st/f4/stm32f4.dtsi:439 */
			status = "disabled";            /* in zephyr/dts/arm/st/f4/stm32f4.dtsi:440 */

			/* node '/soc/timers@40000c00/pwm' defined in zephyr/dts/arm/st/f4/stm32f4.dtsi:442 */
			pwm {
				compatible = "st,stm32-pwm"; /* in zephyr/dts/arm/st/f4/stm32f4.dtsi:443 */
				status = "disabled";         /* in zephyr/dts/arm/st/f4/stm32f4.dtsi:444 */
				#pwm-cells = < 0x3 >;        /* in zephyr/dts/arm/st/f4/stm32f4.dtsi:445 */
			};

			/* node '/soc/timers@40000c00/counter' defined in zephyr/dts/arm/st/f4/stm32f4.dtsi:448 */
			counter {
				compatible = "st,stm32-counter"; /* in zephyr/dts/arm/st/f4/stm32f4.dtsi:449 */
				status = "disabled";             /* in zephyr/dts/arm/st/f4/stm32f4.dtsi:450 */
			};

			/* node '/soc/timers@40000c00/qdec' defined in zephyr/dts/arm/st/f4/stm32f4.dtsi:453 */
			qdec {
				compatible = "st,stm32-qdec";    /* in zephyr/dts/arm/st/f4/stm32f4.dtsi:454 */
				status = "disabled";             /* in zephyr/dts/arm/st/f4/stm32f4.dtsi:455 */
				st,input-filter-level = < 0x0 >; /* in zephyr/dts/arm/st/f4/stm32f4.dtsi:456 */
			};
		};

		/* node '/soc/timers@40014000' defined in zephyr/dts/arm/st/f4/stm32f4.dtsi:460 */
		timers9: timers@40014000 {
			compatible = "st,stm32-timers"; /* in zephyr/dts/arm/st/f4/stm32f4.dtsi:461 */
			reg = < 0x40014000 0x400 >;     /* in zephyr/dts/arm/st/f4/stm32f4.dtsi:462 */
			clocks = < &rcc 0x44 0x10000 >; /* in zephyr/dts/arm/st/f4/stm32f4.dtsi:463 */
			resets = < &rctl 0x490 >;       /* in zephyr/dts/arm/st/f4/stm32f4.dtsi:464 */
			interrupts = < 0x18 0x0 >;      /* in zephyr/dts/arm/st/f4/stm32f4.dtsi:465 */
			interrupt-names = "global";     /* in zephyr/dts/arm/st/f4/stm32f4.dtsi:466 */
			st,prescaler = < 0x0 >;         /* in zephyr/dts/arm/st/f4/stm32f4.dtsi:467 */
			status = "disabled";            /* in zephyr/dts/arm/st/f4/stm32f4.dtsi:468 */

			/* node '/soc/timers@40014000/pwm' defined in zephyr/dts/arm/st/f4/stm32f4.dtsi:470 */
			pwm {
				compatible = "st,stm32-pwm"; /* in zephyr/dts/arm/st/f4/stm32f4.dtsi:471 */
				status = "disabled";         /* in zephyr/dts/arm/st/f4/stm32f4.dtsi:472 */
				#pwm-cells = < 0x3 >;        /* in zephyr/dts/arm/st/f4/stm32f4.dtsi:473 */
			};

			/* node '/soc/timers@40014000/counter' defined in zephyr/dts/arm/st/f4/stm32f4.dtsi:476 */
			counter {
				compatible = "st,stm32-counter"; /* in zephyr/dts/arm/st/f4/stm32f4.dtsi:477 */
				status = "disabled";             /* in zephyr/dts/arm/st/f4/stm32f4.dtsi:478 */
			};
		};

		/* node '/soc/timers@40014400' defined in zephyr/dts/arm/st/f4/stm32f4.dtsi:482 */
		timers10: timers@40014400 {
			compatible = "st,stm32-timers"; /* in zephyr/dts/arm/st/f4/stm32f4.dtsi:483 */
			reg = < 0x40014400 0x400 >;     /* in zephyr/dts/arm/st/f4/stm32f4.dtsi:484 */
			clocks = < &rcc 0x44 0x20000 >; /* in zephyr/dts/arm/st/f4/stm32f4.dtsi:485 */
			resets = < &rctl 0x491 >;       /* in zephyr/dts/arm/st/f4/stm32f4.dtsi:486 */
			interrupts = < 0x19 0x0 >;      /* in zephyr/dts/arm/st/f4/stm32f4.dtsi:487 */
			interrupt-names = "global";     /* in zephyr/dts/arm/st/f4/stm32f4.dtsi:488 */
			st,prescaler = < 0x0 >;         /* in zephyr/dts/arm/st/f4/stm32f4.dtsi:489 */
			status = "disabled";            /* in zephyr/dts/arm/st/f4/stm32f4.dtsi:490 */

			/* node '/soc/timers@40014400/pwm' defined in zephyr/dts/arm/st/f4/stm32f4.dtsi:492 */
			pwm {
				compatible = "st,stm32-pwm"; /* in zephyr/dts/arm/st/f4/stm32f4.dtsi:493 */
				status = "disabled";         /* in zephyr/dts/arm/st/f4/stm32f4.dtsi:494 */
				#pwm-cells = < 0x3 >;        /* in zephyr/dts/arm/st/f4/stm32f4.dtsi:495 */
			};

			/* node '/soc/timers@40014400/counter' defined in zephyr/dts/arm/st/f4/stm32f4.dtsi:498 */
			counter {
				compatible = "st,stm32-counter"; /* in zephyr/dts/arm/st/f4/stm32f4.dtsi:499 */
				status = "disabled";             /* in zephyr/dts/arm/st/f4/stm32f4.dtsi:500 */
			};
		};

		/* node '/soc/timers@40014800' defined in zephyr/dts/arm/st/f4/stm32f4.dtsi:504 */
		timers11: timers@40014800 {
			compatible = "st,stm32-timers"; /* in zephyr/dts/arm/st/f4/stm32f4.dtsi:505 */
			reg = < 0x40014800 0x400 >;     /* in zephyr/dts/arm/st/f4/stm32f4.dtsi:506 */
			clocks = < &rcc 0x44 0x40000 >; /* in zephyr/dts/arm/st/f4/stm32f4.dtsi:507 */
			resets = < &rctl 0x492 >;       /* in zephyr/dts/arm/st/f4/stm32f4.dtsi:508 */
			interrupts = < 0x1a 0x0 >;      /* in zephyr/dts/arm/st/f4/stm32f4.dtsi:509 */
			interrupt-names = "global";     /* in zephyr/dts/arm/st/f4/stm32f4.dtsi:510 */
			st,prescaler = < 0x0 >;         /* in zephyr/dts/arm/st/f4/stm32f4.dtsi:511 */
			status = "disabled";            /* in zephyr/dts/arm/st/f4/stm32f4.dtsi:512 */

			/* node '/soc/timers@40014800/pwm' defined in zephyr/dts/arm/st/f4/stm32f4.dtsi:514 */
			pwm {
				compatible = "st,stm32-pwm"; /* in zephyr/dts/arm/st/f4/stm32f4.dtsi:515 */
				status = "disabled";         /* in zephyr/dts/arm/st/f4/stm32f4.dtsi:516 */
				#pwm-cells = < 0x3 >;        /* in zephyr/dts/arm/st/f4/stm32f4.dtsi:517 */
			};

			/* node '/soc/timers@40014800/counter' defined in zephyr/dts/arm/st/f4/stm32f4.dtsi:520 */
			counter {
				compatible = "st,stm32-counter"; /* in zephyr/dts/arm/st/f4/stm32f4.dtsi:521 */
				status = "disabled";             /* in zephyr/dts/arm/st/f4/stm32f4.dtsi:522 */
			};
		};

		/* node '/soc/rtc@40002800' defined in zephyr/dts/arm/st/f4/stm32f4.dtsi:526 */
		rtc: rtc@40002800 {
			compatible = "st,stm32-rtc";       /* in zephyr/dts/arm/st/f4/stm32f4.dtsi:527 */
			reg = < 0x40002800 0x400 >;        /* in zephyr/dts/arm/st/f4/stm32f4.dtsi:528 */
			interrupts = < 0x29 0x0 >;         /* in zephyr/dts/arm/st/f4/stm32f4.dtsi:529 */
			prescaler = < 0x8000 >;            /* in zephyr/dts/arm/st/f4/stm32f4.dtsi:531 */
			alarms-count = < 0x2 >;            /* in zephyr/dts/arm/st/f4/stm32f4.dtsi:532 */
			alrm-exti-line = < 0x11 >;         /* in zephyr/dts/arm/st/f4/stm32f4.dtsi:533 */
			clocks = < &rcc 0x40 0x10000000 >,
			         < &rcc 0x3 0x10c80070 >;  /* in zephyr/boards/weact/blackpill_f411ce/blackpill_f411ce.dts:115 */
			status = "okay";                   /* in zephyr/boards/weact/blackpill_f411ce/blackpill_f411ce.dts:117 */

			/* node '/soc/rtc@40002800/backup_regs' defined in zephyr/dts/arm/st/f4/stm32f4.dtsi:536 */
			bbram: backup_regs {
				compatible = "st,stm32-bbram"; /* in zephyr/dts/arm/st/f4/stm32f4.dtsi:537 */
				st,backup-regs = < 0x14 >;     /* in zephyr/dts/arm/st/f4/stm32f4.dtsi:538 */
				status = "disabled";           /* in zephyr/dts/arm/st/f4/stm32f4.dtsi:539 */
			};
		};

		/* node '/soc/adc@40012000' defined in zephyr/dts/arm/st/f4/stm32f4.dtsi:543 */
		adc1: adc@40012000 {
			compatible = "st,stm32f4-adc",
			             "st,stm32-adc";                                 /* in zephyr/dts/arm/st/f4/stm32f4.dtsi:544 */
			reg = < 0x40012000 0x400 >;                                  /* in zephyr/dts/arm/st/f4/stm32f4.dtsi:545 */
			clocks = < &rcc 0x44 0x100 >;                                /* in zephyr/dts/arm/st/f4/stm32f4.dtsi:546 */
			interrupts = < 0x12 0x0 >;                                   /* in zephyr/dts/arm/st/f4/stm32f4.dtsi:547 */
			#io-channel-cells = < 0x1 >;                                 /* in zephyr/dts/arm/st/f4/stm32f4.dtsi:549 */
			resolutions = < 0x607804 0x517804 0x427804 0x337804 >;       /* in zephyr/dts/arm/st/f4/stm32f4.dtsi:550 */
			sampling-times = < 0x3 0xf 0x1c 0x38 0x54 0x70 0x90 0x1e0 >; /* in zephyr/dts/arm/st/f4/stm32f4.dtsi:554 */
			st,adc-sequencer = "FULLY_CONFIGURABLE";                     /* in zephyr/dts/arm/st/f4/stm32f4.dtsi:556 */
			st,adc-oversampler = "OVERSAMPLER_NONE";                     /* in zephyr/dts/arm/st/f4/stm32f4.dtsi:557 */
			pinctrl-0 = < &adc1_in1_pa1 >;                               /* in zephyr/boards/weact/blackpill_f411ce/blackpill_f411ce.dts:127 */
			pinctrl-names = "default";                                   /* in zephyr/boards/weact/blackpill_f411ce/blackpill_f411ce.dts:128 */
			st,adc-clock-source = "SYNC";                                /* in zephyr/boards/weact/blackpill_f411ce/blackpill_f411ce.dts:129 */
			st,adc-prescaler = < 0x2 >;                                  /* in zephyr/boards/weact/blackpill_f411ce/blackpill_f411ce.dts:130 */
			status = "okay";                                             /* in zephyr/boards/weact/blackpill_f411ce/blackpill_f411ce.dts:131 */
			phandle = < 0x18 >;                                          /* in zephyr/dts/arm/st/f4/stm32f411.dtsi:72 */
		};

		/* node '/soc/dma@40026000' defined in zephyr/dts/arm/st/f4/stm32f4.dtsi:560 */
		dma1: dma@40026000 {
			compatible = "st,stm32-dma-v1";                                                      /* in zephyr/dts/arm/st/f4/stm32f4.dtsi:561 */
			#dma-cells = < 0x4 >;                                                                /* in zephyr/dts/arm/st/f4/stm32f4.dtsi:562 */
			reg = < 0x40026000 0x400 >;                                                          /* in zephyr/dts/arm/st/f4/stm32f4.dtsi:563 */
			interrupts = < 0xb 0x0 0xc 0x0 0xd 0x0 0xe 0x0 0xf 0x0 0x10 0x0 0x11 0x0 0x2f 0x0 >; /* in zephyr/dts/arm/st/f4/stm32f4.dtsi:564 */
			clocks = < &rcc 0x30 0x200000 >;                                                     /* in zephyr/dts/arm/st/f4/stm32f4.dtsi:565 */
			status = "disabled";                                                                 /* in zephyr/dts/arm/st/f4/stm32f4.dtsi:566 */
			phandle = < 0x13 >;                                                                  /* in zephyr/dts/arm/st/f4/stm32f401.dtsi:58 */
		};

		/* node '/soc/dma@40026400' defined in zephyr/dts/arm/st/f4/stm32f4.dtsi:569 */
		dma2: dma@40026400 {
			compatible = "st,stm32-dma-v1";                                                           /* in zephyr/dts/arm/st/f4/stm32f4.dtsi:570 */
			#dma-cells = < 0x4 >;                                                                     /* in zephyr/dts/arm/st/f4/stm32f4.dtsi:571 */
			reg = < 0x40026400 0x400 >;                                                               /* in zephyr/dts/arm/st/f4/stm32f4.dtsi:572 */
			interrupts = < 0x38 0x0 0x39 0x0 0x3a 0x0 0x3b 0x0 0x3c 0x0 0x44 0x0 0x45 0x0 0x46 0x0 >; /* in zephyr/dts/arm/st/f4/stm32f4.dtsi:573 */
			clocks = < &rcc 0x30 0x400000 >;                                                          /* in zephyr/dts/arm/st/f4/stm32f4.dtsi:574 */
			st,mem2mem;                                                                               /* in zephyr/dts/arm/st/f4/stm32f4.dtsi:575 */
			status = "disabled";                                                                      /* in zephyr/dts/arm/st/f4/stm32f4.dtsi:576 */
			phandle = < 0x14 >;                                                                       /* in zephyr/dts/arm/st/f4/stm32f411.dtsi:38 */
		};

		/* node '/soc/sdmmc@40012c00' defined in zephyr/dts/arm/st/f4/stm32f4.dtsi:579 */
		sdmmc1: sdmmc@40012c00 {
			compatible = "st,stm32-sdmmc"; /* in zephyr/dts/arm/st/f4/stm32f4.dtsi:580 */
			reg = < 0x40012c00 0x400 >;    /* in zephyr/dts/arm/st/f4/stm32f4.dtsi:581 */
			clocks = < &rcc 0x44 0x800 >,
			         < &rcc 0x7 0xff >;    /* in zephyr/dts/arm/st/f4/stm32f4.dtsi:582 */
			resets = < &rctl 0x48b >;      /* in zephyr/dts/arm/st/f4/stm32f4.dtsi:584 */
			interrupts = < 0x31 0x0 >;     /* in zephyr/dts/arm/st/f4/stm32f4.dtsi:585 */
			status = "disabled";           /* in zephyr/dts/arm/st/f4/stm32f4.dtsi:586 */
		};

		/* node '/soc/spi@40003800' defined in zephyr/dts/arm/st/f4/stm32f401.dtsi:21 */
		spi2: spi@40003800 {
			compatible = "st,stm32-spi";   /* in zephyr/dts/arm/st/f4/stm32f401.dtsi:22 */
			#address-cells = < 0x1 >;      /* in zephyr/dts/arm/st/f4/stm32f401.dtsi:23 */
			#size-cells = < 0x0 >;         /* in zephyr/dts/arm/st/f4/stm32f401.dtsi:24 */
			reg = < 0x40003800 0x400 >;    /* in zephyr/dts/arm/st/f4/stm32f401.dtsi:25 */
			clocks = < &rcc 0x40 0x4000 >; /* in zephyr/dts/arm/st/f4/stm32f401.dtsi:26 */
			interrupts = < 0x24 0x5 >;     /* in zephyr/dts/arm/st/f4/stm32f401.dtsi:27 */
			status = "disabled";           /* in zephyr/dts/arm/st/f4/stm32f401.dtsi:28 */
		};

		/* node '/soc/spi@40003c00' defined in zephyr/dts/arm/st/f4/stm32f401.dtsi:31 */
		spi3: spi@40003c00 {
			compatible = "st,stm32-spi";   /* in zephyr/dts/arm/st/f4/stm32f401.dtsi:32 */
			#address-cells = < 0x1 >;      /* in zephyr/dts/arm/st/f4/stm32f401.dtsi:33 */
			#size-cells = < 0x0 >;         /* in zephyr/dts/arm/st/f4/stm32f401.dtsi:34 */
			reg = < 0x40003c00 0x400 >;    /* in zephyr/dts/arm/st/f4/stm32f401.dtsi:35 */
			clocks = < &rcc 0x40 0x8000 >; /* in zephyr/dts/arm/st/f4/stm32f401.dtsi:36 */
			interrupts = < 0x33 0x5 >;     /* in zephyr/dts/arm/st/f4/stm32f401.dtsi:37 */
			status = "disabled";           /* in zephyr/dts/arm/st/f4/stm32f401.dtsi:38 */
		};

		/* node '/soc/spi@40013400' defined in zephyr/dts/arm/st/f4/stm32f401.dtsi:41 */
		spi4: spi@40013400 {
			compatible = "st,stm32-spi";   /* in zephyr/dts/arm/st/f4/stm32f401.dtsi:42 */
			#address-cells = < 0x1 >;      /* in zephyr/dts/arm/st/f4/stm32f401.dtsi:43 */
			#size-cells = < 0x0 >;         /* in zephyr/dts/arm/st/f4/stm32f401.dtsi:44 */
			reg = < 0x40013400 0x400 >;    /* in zephyr/dts/arm/st/f4/stm32f401.dtsi:45 */
			clocks = < &rcc 0x44 0x2000 >; /* in zephyr/dts/arm/st/f4/stm32f401.dtsi:46 */
			interrupts = < 0x54 0x5 >;     /* in zephyr/dts/arm/st/f4/stm32f401.dtsi:47 */
			status = "disabled";           /* in zephyr/dts/arm/st/f4/stm32f401.dtsi:48 */
		};

		/* node '/soc/i2s@40003800' defined in zephyr/dts/arm/st/f4/stm32f401.dtsi:51 */
		i2s2: i2s@40003800 {
			compatible = "st,stm32-i2s";                                /* in zephyr/dts/arm/st/f4/stm32f401.dtsi:52 */
			#address-cells = < 0x1 >;                                   /* in zephyr/dts/arm/st/f4/stm32f401.dtsi:53 */
			#size-cells = < 0x0 >;                                      /* in zephyr/dts/arm/st/f4/stm32f401.dtsi:54 */
			reg = < 0x40003800 0x400 >;                                 /* in zephyr/dts/arm/st/f4/stm32f401.dtsi:55 */
			clocks = < &rcc 0x40 0x4000 >;                              /* in zephyr/dts/arm/st/f4/stm32f401.dtsi:56 */
			interrupts = < 0x24 0x5 >;                                  /* in zephyr/dts/arm/st/f4/stm32f401.dtsi:57 */
			dmas = < &dma1 0x4 0x0 0x400 0x3 &dma1 0x3 0x0 0x400 0x3 >; /* in zephyr/dts/arm/st/f4/stm32f401.dtsi:58 */
			dma-names = "tx",
			            "rx";                                           /* in zephyr/dts/arm/st/f4/stm32f401.dtsi:60 */
			status = "disabled";                                        /* in zephyr/dts/arm/st/f4/stm32f401.dtsi:61 */
		};

		/* node '/soc/i2s@40003c00' defined in zephyr/dts/arm/st/f4/stm32f401.dtsi:64 */
		i2s3: i2s@40003c00 {
			compatible = "st,stm32-i2s";                                /* in zephyr/dts/arm/st/f4/stm32f401.dtsi:65 */
			#address-cells = < 0x1 >;                                   /* in zephyr/dts/arm/st/f4/stm32f401.dtsi:66 */
			#size-cells = < 0x0 >;                                      /* in zephyr/dts/arm/st/f4/stm32f401.dtsi:67 */
			reg = < 0x40003c00 0x400 >;                                 /* in zephyr/dts/arm/st/f4/stm32f401.dtsi:68 */
			clocks = < &rcc 0x40 0x8000 >;                              /* in zephyr/dts/arm/st/f4/stm32f401.dtsi:69 */
			interrupts = < 0x33 0x5 >;                                  /* in zephyr/dts/arm/st/f4/stm32f401.dtsi:70 */
			dmas = < &dma1 0x5 0x0 0x400 0x3 &dma1 0x0 0x0 0x400 0x3 >; /* in zephyr/dts/arm/st/f4/stm32f401.dtsi:71 */
			dma-names = "tx",
			            "rx";                                           /* in zephyr/dts/arm/st/f4/stm32f401.dtsi:73 */
			status = "disabled";                                        /* in zephyr/dts/arm/st/f4/stm32f401.dtsi:74 */
		};

		/* node '/soc/spi@40015000' defined in zephyr/dts/arm/st/f4/stm32f411.dtsi:21 */
		spi5: spi@40015000 {
			compatible = "st,stm32-spi";     /* in zephyr/dts/arm/st/f4/stm32f411.dtsi:22 */
			#address-cells = < 0x1 >;        /* in zephyr/dts/arm/st/f4/stm32f411.dtsi:23 */
			#size-cells = < 0x0 >;           /* in zephyr/dts/arm/st/f4/stm32f411.dtsi:24 */
			reg = < 0x40015000 0x400 >;      /* in zephyr/dts/arm/st/f4/stm32f411.dtsi:25 */
			clocks = < &rcc 0x44 0x100000 >; /* in zephyr/dts/arm/st/f4/stm32f411.dtsi:26 */
			interrupts = < 0x55 0x5 >;       /* in zephyr/dts/arm/st/f4/stm32f411.dtsi:27 */
			status = "disabled";             /* in zephyr/dts/arm/st/f4/stm32f411.dtsi:28 */
		};

		/* node '/soc/i2s@40013000' defined in zephyr/dts/arm/st/f4/stm32f411.dtsi:31 */
		i2s1: i2s@40013000 {
			compatible = "st,stm32-i2s";                                /* in zephyr/dts/arm/st/f4/stm32f411.dtsi:32 */
			#address-cells = < 0x1 >;                                   /* in zephyr/dts/arm/st/f4/stm32f411.dtsi:33 */
			#size-cells = < 0x0 >;                                      /* in zephyr/dts/arm/st/f4/stm32f411.dtsi:34 */
			reg = < 0x40013000 0x400 >;                                 /* in zephyr/dts/arm/st/f4/stm32f411.dtsi:35 */
			clocks = < &rcc 0x44 0x1000 >;                              /* in zephyr/dts/arm/st/f4/stm32f411.dtsi:36 */
			interrupts = < 0x23 0x5 >;                                  /* in zephyr/dts/arm/st/f4/stm32f411.dtsi:37 */
			dmas = < &dma2 0x3 0x3 0x400 0x3 &dma2 0x2 0x3 0x400 0x3 >; /* in zephyr/dts/arm/st/f4/stm32f411.dtsi:38 */
			dma-names = "tx",
			            "rx";                                           /* in zephyr/dts/arm/st/f4/stm32f411.dtsi:40 */
			status = "disabled";                                        /* in zephyr/dts/arm/st/f4/stm32f411.dtsi:41 */
		};

		/* node '/soc/i2s@40013400' defined in zephyr/dts/arm/st/f4/stm32f411.dtsi:44 */
		i2s4: i2s@40013400 {
			compatible = "st,stm32-i2s";                                /* in zephyr/dts/arm/st/f4/stm32f411.dtsi:45 */
			#address-cells = < 0x1 >;                                   /* in zephyr/dts/arm/st/f4/stm32f411.dtsi:46 */
			#size-cells = < 0x0 >;                                      /* in zephyr/dts/arm/st/f4/stm32f411.dtsi:47 */
			reg = < 0x40013400 0x400 >;                                 /* in zephyr/dts/arm/st/f4/stm32f411.dtsi:48 */
			clocks = < &rcc 0x44 0x2000 >;                              /* in zephyr/dts/arm/st/f4/stm32f411.dtsi:49 */
			interrupts = < 0x54 0x5 >;                                  /* in zephyr/dts/arm/st/f4/stm32f411.dtsi:50 */
			dmas = < &dma2 0x1 0x4 0x400 0x3 &dma2 0x0 0x4 0x400 0x3 >; /* in zephyr/dts/arm/st/f4/stm32f411.dtsi:51 */
			dma-names = "tx",
			            "rx";                                           /* in zephyr/dts/arm/st/f4/stm32f411.dtsi:53 */
			status = "disabled";                                        /* in zephyr/dts/arm/st/f4/stm32f411.dtsi:54 */
		};

		/* node '/soc/i2s@40015000' defined in zephyr/dts/arm/st/f4/stm32f411.dtsi:57 */
		i2s5: i2s@40015000 {
			compatible = "st,stm32-i2s";                                /* in zephyr/dts/arm/st/f4/stm32f411.dtsi:58 */
			#address-cells = < 0x1 >;                                   /* in zephyr/dts/arm/st/f4/stm32f411.dtsi:59 */
			#size-cells = < 0x0 >;                                      /* in zephyr/dts/arm/st/f4/stm32f411.dtsi:60 */
			reg = < 0x40015000 0x400 >;                                 /* in zephyr/dts/arm/st/f4/stm32f411.dtsi:61 */
			clocks = < &rcc 0x44 0x100000 >;                            /* in zephyr/dts/arm/st/f4/stm32f411.dtsi:62 */
			interrupts = < 0x55 0x5 >;                                  /* in zephyr/dts/arm/st/f4/stm32f411.dtsi:63 */
			dmas = < &dma2 0x6 0x7 0x400 0x3 &dma2 0x5 0x7 0x400 0x3 >; /* in zephyr/dts/arm/st/f4/stm32f411.dtsi:64 */
			dma-names = "tx",
			            "rx";                                           /* in zephyr/dts/arm/st/f4/stm32f411.dtsi:66 */
			status = "disabled";                                        /* in zephyr/dts/arm/st/f4/stm32f411.dtsi:67 */
		};
	};

	/* node '/cpus' defined in zephyr/dts/arm/st/f4/stm32f4.dtsi:30 */
	cpus {
		#address-cells = < 0x1 >; /* in zephyr/dts/arm/st/f4/stm32f4.dtsi:31 */
		#size-cells = < 0x0 >;    /* in zephyr/dts/arm/st/f4/stm32f4.dtsi:32 */

		/* node '/cpus/cpu@0' defined in zephyr/dts/arm/st/f4/stm32f4.dtsi:34 */
		cpu0: cpu@0 {
			device_type = "cpu";           /* in zephyr/dts/arm/st/f4/stm32f4.dtsi:35 */
			compatible = "arm,cortex-m4f"; /* in zephyr/dts/arm/st/f4/stm32f4.dtsi:36 */
			reg = < 0x0 >;                 /* in zephyr/dts/arm/st/f4/stm32f4.dtsi:37 */
			cpu-power-states = < &stop >;  /* in zephyr/dts/arm/st/f4/stm32f4.dtsi:38 */
		};

		/* node '/cpus/power-states' defined in zephyr/dts/arm/st/f4/stm32f4.dtsi:41 */
		power-states {

			/* node '/cpus/power-states/stop' defined in zephyr/dts/arm/st/f4/stm32f4.dtsi:42 */
			stop: stop {
				compatible = "zephyr,power-state";    /* in zephyr/dts/arm/st/f4/stm32f4.dtsi:43 */
				power-state-name = "suspend-to-idle"; /* in zephyr/dts/arm/st/f4/stm32f4.dtsi:44 */
				min-residency-us = < 0x190 >;         /* in zephyr/dts/arm/st/f4/stm32f4.dtsi:51 */
				exit-latency-us = < 0x12c >;          /* in zephyr/dts/arm/st/f4/stm32f4.dtsi:52 */
				phandle = < 0x15 >;                   /* in zephyr/dts/arm/st/f4/stm32f4.dtsi:38 */
			};
		};
	};

	/* node '/memory@20000000' defined in zephyr/dts/arm/st/f4/stm32f4.dtsi:57 */
	sram0: memory@20000000 {
		compatible = "mmio-sram";     /* in zephyr/dts/arm/st/f4/stm32f4.dtsi:58 */
		reg = < 0x20000000 0x20000 >; /* in zephyr/dts/arm/st/f4/stm32f411Xe.dtsi:12 */
	};

	/* node '/clocks' defined in zephyr/dts/arm/st/f4/stm32f4.dtsi:61 */
	clocks {

		/* node '/clocks/clk-hse' defined in zephyr/dts/arm/st/f4/stm32f4.dtsi:62 */
		clk_hse: clk-hse {
			#clock-cells = < 0x0 >;            /* in zephyr/dts/arm/st/f4/stm32f4.dtsi:63 */
			compatible = "st,stm32-hse-clock"; /* in zephyr/dts/arm/st/f4/stm32f4.dtsi:64 */
			clock-frequency = < 0x17d7840 >;   /* in zephyr/boards/weact/blackpill_f411ce/blackpill_f411ce.dts:139 */
			status = "okay";                   /* in zephyr/boards/weact/blackpill_f411ce/blackpill_f411ce.dts:140 */
			phandle = < 0x16 >;                /* in zephyr/boards/weact/blackpill_f411ce/blackpill_f411ce.dts:148 */
		};

		/* node '/clocks/clk-hsi' defined in zephyr/dts/arm/st/f4/stm32f4.dtsi:68 */
		clk_hsi: clk-hsi {
			#clock-cells = < 0x0 >;         /* in zephyr/dts/arm/st/f4/stm32f4.dtsi:69 */
			compatible = "fixed-clock";     /* in zephyr/dts/arm/st/f4/stm32f4.dtsi:70 */
			clock-frequency = < 0xf42400 >; /* in zephyr/dts/arm/st/f4/stm32f4.dtsi:71 */
			status = "disabled";            /* in zephyr/dts/arm/st/f4/stm32f4.dtsi:72 */
		};

		/* node '/clocks/clk-lse' defined in zephyr/dts/arm/st/f4/stm32f4.dtsi:75 */
		clk_lse: clk-lse {
			#clock-cells = < 0x0 >;       /* in zephyr/dts/arm/st/f4/stm32f4.dtsi:76 */
			compatible = "fixed-clock";   /* in zephyr/dts/arm/st/f4/stm32f4.dtsi:77 */
			clock-frequency = < 0x8000 >; /* in zephyr/dts/arm/st/f4/stm32f4.dtsi:78 */
			status = "disabled";          /* in zephyr/dts/arm/st/f4/stm32f4.dtsi:79 */
		};

		/* node '/clocks/clk-lsi' defined in zephyr/dts/arm/st/f4/stm32f4.dtsi:82 */
		clk_lsi: clk-lsi {
			#clock-cells = < 0x0 >;       /* in zephyr/dts/arm/st/f4/stm32f4.dtsi:83 */
			compatible = "fixed-clock";   /* in zephyr/dts/arm/st/f4/stm32f4.dtsi:84 */
			clock-frequency = < 0x7d00 >; /* in zephyr/dts/arm/st/f4/stm32f4.dtsi:85 */
			status = "okay";              /* in zephyr/boards/weact/blackpill_f411ce/blackpill_f411ce.dts:135 */
		};

		/* node '/clocks/pll' defined in zephyr/dts/arm/st/f4/stm32f4.dtsi:89 */
		pll: pll {
			#clock-cells = < 0x0 >;              /* in zephyr/dts/arm/st/f4/stm32f4.dtsi:90 */
			compatible = "st,stm32f4-pll-clock"; /* in zephyr/dts/arm/st/f4/stm32f4.dtsi:91 */
			div-m = < 0x19 >;                    /* in zephyr/boards/weact/blackpill_f411ce/blackpill_f411ce.dts:144 */
			mul-n = < 0xc0 >;                    /* in zephyr/boards/weact/blackpill_f411ce/blackpill_f411ce.dts:145 */
			div-p = < 0x2 >;                     /* in zephyr/boards/weact/blackpill_f411ce/blackpill_f411ce.dts:146 */
			div-q = < 0x4 >;                     /* in zephyr/boards/weact/blackpill_f411ce/blackpill_f411ce.dts:147 */
			clocks = < &clk_hse >;               /* in zephyr/boards/weact/blackpill_f411ce/blackpill_f411ce.dts:148 */
			status = "okay";                     /* in zephyr/boards/weact/blackpill_f411ce/blackpill_f411ce.dts:149 */
			phandle = < 0x2 >;                   /* in zephyr/boards/weact/blackpill_f411ce/blackpill_f411ce.dts:153 */
		};

		/* node '/clocks/plli2s' defined in zephyr/dts/arm/st/f4/stm32f401.dtsi:11 */
		plli2s: plli2s {
			#clock-cells = < 0x0 >;                   /* in zephyr/dts/arm/st/f4/stm32f411.dtsi:12 */
			compatible = "st,stm32f411-plli2s-clock"; /* in zephyr/dts/arm/st/f4/stm32f411.dtsi:13 */
			status = "disabled";                      /* in zephyr/dts/arm/st/f4/stm32f411.dtsi:14 */
		};
	};

	/* node '/mcos' defined in zephyr/dts/arm/st/f4/stm32f4.dtsi:96 */
	mcos {

		/* node '/mcos/mco1' defined in zephyr/dts/arm/st/f4/stm32f4.dtsi:97 */
		mco1: mco1 {
			compatible = "st,stm32-clock-mco"; /* in zephyr/dts/arm/st/f4/stm32f4.dtsi:98 */
			status = "disabled";               /* in zephyr/dts/arm/st/f4/stm32f4.dtsi:99 */
		};

		/* node '/mcos/mco2' defined in zephyr/dts/arm/st/f4/stm32f4.dtsi:102 */
		mco2: mco2 {
			compatible = "st,stm32-clock-mco"; /* in zephyr/dts/arm/st/f4/stm32f4.dtsi:103 */
			status = "disabled";               /* in zephyr/dts/arm/st/f4/stm32f4.dtsi:104 */
		};
	};

	/* node '/power@40007000' defined in zephyr/dts/arm/st/f4/stm32f4.dtsi:590 */
	pwr: power@40007000 {
		compatible = "st,stm32-pwr"; /* in zephyr/dts/arm/st/f4/stm32f4.dtsi:591 */
		reg = < 0x40007000 0x400 >;  /* in zephyr/dts/arm/st/f4/stm32f4.dtsi:592 */
		status = "disabled";         /* in zephyr/dts/arm/st/f4/stm32f4.dtsi:593 */
		wkup-pins-nb = < 0x1 >;      /* in zephyr/dts/arm/st/f4/stm32f4.dtsi:595 */
		#address-cells = < 0x1 >;    /* in zephyr/dts/arm/st/f4/stm32f4.dtsi:597 */
		#size-cells = < 0x0 >;       /* in zephyr/dts/arm/st/f4/stm32f4.dtsi:598 */

		/* node '/power@40007000/wkup-pin@1' defined in zephyr/dts/arm/st/f4/stm32f4.dtsi:600 */
		wkup-pin@1 {
			reg = < 0x1 >;                   /* in zephyr/dts/arm/st/f4/stm32f4.dtsi:601 */
			wkup-gpios = < &gpioa 0x0 0x1 >; /* in zephyr/dts/arm/st/f4/stm32f4.dtsi:602 */
		};
	};

	/* node '/dietemp' defined in zephyr/dts/arm/st/f4/stm32f4.dtsi:606 */
	die_temp: dietemp {
		compatible = "st,stm32-temp-cal"; /* in zephyr/dts/arm/st/f4/stm32f4.dtsi:607 */
		ts-cal1-addr = < 0x1fff7a2c >;    /* in zephyr/dts/arm/st/f4/stm32f4.dtsi:608 */
		ts-cal2-addr = < 0x1fff7a2e >;    /* in zephyr/dts/arm/st/f4/stm32f4.dtsi:609 */
		ts-cal1-temp = < 0x1e >;          /* in zephyr/dts/arm/st/f4/stm32f4.dtsi:610 */
		ts-cal2-temp = < 0x6e >;          /* in zephyr/dts/arm/st/f4/stm32f4.dtsi:611 */
		ts-cal-vrefanalog = < 0xce4 >;    /* in zephyr/dts/arm/st/f4/stm32f4.dtsi:612 */
		status = "disabled";              /* in zephyr/dts/arm/st/f4/stm32f4.dtsi:614 */
		io-channels = < &adc1 0x12 >;     /* in zephyr/dts/arm/st/f4/stm32f411.dtsi:72 */
	};

	/* node '/vref' defined in zephyr/dts/arm/st/f4/stm32f4.dtsi:617 */
	vref: vref {
		compatible = "st,stm32-vref";      /* in zephyr/dts/arm/st/f4/stm32f4.dtsi:618 */
		vrefint-cal-addr = < 0x1fff7a2a >; /* in zephyr/dts/arm/st/f4/stm32f4.dtsi:619 */
		vrefint-cal-mv = < 0xce4 >;        /* in zephyr/dts/arm/st/f4/stm32f4.dtsi:620 */
		io-channels = < &adc1 0x11 >;      /* in zephyr/dts/arm/st/f4/stm32f4.dtsi:621 */
		status = "okay";                   /* in zephyr/boards/weact/blackpill_f411ce/blackpill_f411ce.dts:161 */
	};

	/* node '/vbat' defined in zephyr/dts/arm/st/f4/stm32f4.dtsi:625 */
	vbat: vbat {
		compatible = "st,stm32-vbat"; /* in zephyr/dts/arm/st/f4/stm32f4.dtsi:626 */
		ratio = < 0x4 >;              /* in zephyr/dts/arm/st/f4/stm32f4.dtsi:627 */
		io-channels = < &adc1 0x12 >; /* in zephyr/dts/arm/st/f4/stm32f4.dtsi:628 */
		status = "okay";              /* in zephyr/boards/weact/blackpill_f411ce/blackpill_f411ce.dts:165 */
	};

	/* node '/otgfs_phy' defined in zephyr/dts/arm/st/f4/stm32f4.dtsi:632 */
	otgfs_phy: otgfs_phy {
		compatible = "usb-nop-xceiv"; /* in zephyr/dts/arm/st/f4/stm32f4.dtsi:633 */
		#phy-cells = < 0x0 >;         /* in zephyr/dts/arm/st/f4/stm32f4.dtsi:634 */
		phandle = < 0xd >;            /* in zephyr/dts/arm/st/f4/stm32f4.dtsi:319 */
	};

	/* node '/smbus1' defined in zephyr/dts/arm/st/f4/stm32f4.dtsi:637 */
	smbus1: smbus1 {
		compatible = "st,stm32-smbus"; /* in zephyr/dts/arm/st/f4/stm32f4.dtsi:638 */
		#address-cells = < 0x1 >;      /* in zephyr/dts/arm/st/f4/stm32f4.dtsi:639 */
		#size-cells = < 0x0 >;         /* in zephyr/dts/arm/st/f4/stm32f4.dtsi:640 */
		i2c = < &i2c1 >;               /* in zephyr/dts/arm/st/f4/stm32f4.dtsi:641 */
		status = "disabled";           /* in zephyr/dts/arm/st/f4/stm32f4.dtsi:642 */
	};

	/* node '/smbus2' defined in zephyr/dts/arm/st/f4/stm32f4.dtsi:645 */
	smbus2: smbus2 {
		compatible = "st,stm32-smbus"; /* in zephyr/dts/arm/st/f4/stm32f4.dtsi:646 */
		#address-cells = < 0x1 >;      /* in zephyr/dts/arm/st/f4/stm32f4.dtsi:647 */
		#size-cells = < 0x0 >;         /* in zephyr/dts/arm/st/f4/stm32f4.dtsi:648 */
		i2c = < &i2c2 >;               /* in zephyr/dts/arm/st/f4/stm32f4.dtsi:649 */
		status = "disabled";           /* in zephyr/dts/arm/st/f4/stm32f4.dtsi:650 */
	};

	/* node '/smbus3' defined in zephyr/dts/arm/st/f4/stm32f4.dtsi:653 */
	smbus3: smbus3 {
		compatible = "st,stm32-smbus"; /* in zephyr/dts/arm/st/f4/stm32f4.dtsi:654 */
		#address-cells = < 0x1 >;      /* in zephyr/dts/arm/st/f4/stm32f4.dtsi:655 */
		#size-cells = < 0x0 >;         /* in zephyr/dts/arm/st/f4/stm32f4.dtsi:656 */
		i2c = < &i2c3 >;               /* in zephyr/dts/arm/st/f4/stm32f4.dtsi:657 */
		status = "disabled";           /* in zephyr/dts/arm/st/f4/stm32f4.dtsi:658 */
	};

	/* node '/leds' defined in zephyr/boards/weact/blackpill_f411ce/blackpill_f411ce.dts:24 */
	leds {
		compatible = "gpio-leds"; /* in zephyr/boards/weact/blackpill_f411ce/blackpill_f411ce.dts:25 */

		/* node '/leds/led' defined in zephyr/boards/weact/blackpill_f411ce/blackpill_f411ce.dts:26 */
		user_led: led {
			gpios = < &gpioc 0xd 0x1 >; /* in zephyr/boards/weact/blackpill_f411ce/blackpill_f411ce.dts:27 */
			label = "User LED";         /* in zephyr/boards/weact/blackpill_f411ce/blackpill_f411ce.dts:28 */
		};
	};

	/* node '/gpio_keys' defined in zephyr/boards/weact/blackpill_f411ce/blackpill_f411ce.dts:32 */
	gpio_keys {
		compatible = "gpio-keys"; /* in zephyr/boards/weact/blackpill_f411ce/blackpill_f411ce.dts:33 */

		/* node '/gpio_keys/button' defined in zephyr/boards/weact/blackpill_f411ce/blackpill_f411ce.dts:34 */
		user_button: button {
			label = "KEY";               /* in zephyr/boards/weact/blackpill_f411ce/blackpill_f411ce.dts:35 */
			gpios = < &gpioa 0x0 0x11 >; /* in zephyr/boards/weact/blackpill_f411ce/blackpill_f411ce.dts:36 */
			zephyr,code = < 0xb >;       /* in zephyr/boards/weact/blackpill_f411ce/blackpill_f411ce.dts:37 */
		};
	};
};
